# CH583SFR register map
Vendor: WCH Ltd.; Series: CH58x; File version: 1.1
CPU: RISC-V r0p0, little endian, no MPU, no FPU, 2 interrupt priority bits
Registers are 8-bit, read-write, reset 0x0 unless marked. A register's access mark holds for its fields unless they carry their own. Offsets are from the block's base; [hi:lo] are bit positions.

## I2C
Base 0x40004800
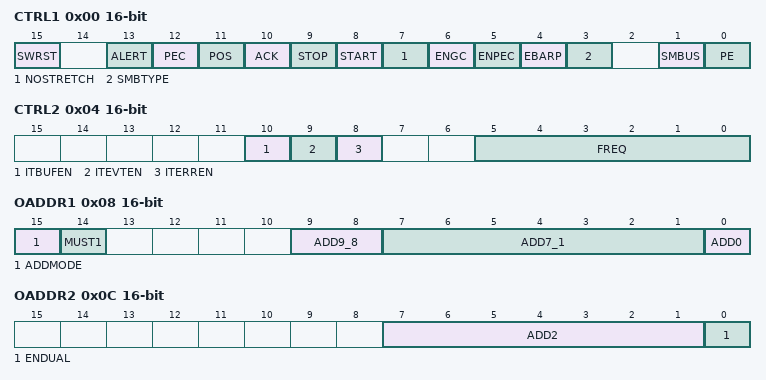
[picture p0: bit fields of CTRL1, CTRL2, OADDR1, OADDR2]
0x00 CTRL1 16-bit — RW, I2C control 1
  [15] SWRST — RW, Software reset
  [13] ALERT — RW, SMBus alert: 0=Releases SMBA pin high, 1=Drives SMBA pin low.
  [12] PEC — RW, Packet error checking: 0=No PEC transfer, 1=PEC transfer (in Tx or Rx mode)
  [11] POS — RW, Acknowledge/PEC Position (for data reception)
  [10] ACK — RW, Acknowledge enable
  [9] STOP — RW, Stop generation: master mode: 0=no stop, 1=stop after the current byte transfer or after the current Start condition is sent; slave mode: 0=no stop, 1=Release the SCL and SDA lines after the current byte transfer
  [8] START — RW, Start generation: master mode: 0=no start, 1=repeated start; slave mode: 0=no start, 1=start at bus free
  [7] NOSTRETCH — RW, Clock stretching disable (Slave mode)
  [6] ENGC — RW, General call enable
  [5] ENPEC — RW, PEC ebable
  [4] EBARP — RW, ARP enable
  [3] SMBTYPE — RW, SMBus type: 0=Device, 1=Host
  [1] SMBUS — RW, SMBUS mode: 0=I2C mode, 1=SMBUS mode
  [0] PE — RW, Peripheral enable
0x04 CTRL2 16-bit — RW, I2C control 2
  [10] ITBUFEN — RW, Buffer interrupt enable
  [9] ITEVTEN — RW, Event interrupt enable
  [8] ITERREN — RW, Error interrupt enable
  [5:0] FREQ — RW, Peripheral clock frequency, The minimum allowed frequency is 2 MHz,the maximum frequency is 36 MHz
0x08 OADDR1 16-bit — RW, I2C own address register 1
  [15] ADDMODE — RW, Addressing mode (slave mode): 0=7-bit slave address, 1=10-bit slave address
  [14] MUST1 — RW, Should always be kept at 1
  [9:8] ADD9_8 — RW, bit[9:8] of address in 10-bit addressing mode
  [7:1] ADD7_1 — RW, bit[7:1] of address
  [0] ADD0 — RW, bit0 of address in 10-bit addressing mode
0x0C OADDR2 16-bit — RW, I2C own address register 2
  [7:1] ADD2 — RW, bit[7:1] of address2
  [0] ENDUAL — RW, Dual addressing mode enable
0x10 DATAR 16-bit — RW, I2C data register
  [7:0] DATAR
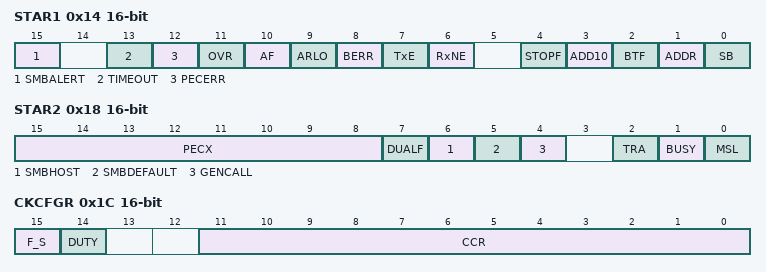
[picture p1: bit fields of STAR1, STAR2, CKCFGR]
0x14 STAR1 16-bit ro — R0, I2C stauts register 1
  [15] SMBALERT — RW0, SMBus alert flag
  [13] TIMEOUT — RW0, Timeout or Tlow error flag
  [12] PECERR — RW0, PEC Error flag in reception
  [11] OVR — RW0, Overrun/Underrun flag
  [10] AF — RW0, Acknowledge failure flag
  [9] ARLO — RW0, Arbitration lost flag (master mode)
  [8] BERR — RW0, Bus error flag
  [7] TxE — RO, Data register empty flag (transmitters)
  [6] RxNE — RO, Data register not empty flag (receivers)
  [4] STOPF — RO, Stop detection flag (slave mode)
  [3] ADD10 — RO, 10-bit header sent flag (Master mode)
  [2] BTF — RO, Byte transfer finished flag
  [1] ADDR — RW0, Address sent (master mode)/matched (slave mode) flag
  [0] SB — RW0, Start bit flag (Master mode)
0x18 STAR2 16-bit ro — R0, I2C status register 2
  [15:8] PECX — RO, Packet error checking register
  [7] DUALF — RO, Dual flag (Slave mode): 0=Received address matched with OAR1, 1=Received address matched with OAR2
  [6] SMBHOST — RO, SMBus host header (Slave mode) received flag
  [5] SMBDEFAULT — RO, SMBus device default address (Slave mode) received flag
  [4] GENCALL — RO, General call address (Slave mode) received flag
  [2] TRA — RO, Trans flag: 0=data bytes received, 1=data bytes transmitted
  [1] BUSY — RO, Bus busy flag
  [0] MSL — RO, Mode statu: 0=Slave mode, 1=Master mode
0x19 PEC ro — R0, I2C Packet error checking register
  [7:0] SPI0_FIFO_COUNT — RO, SPI0 FIFO count status
0x1C CKCFGR 16-bit — RW, I2C clock control register
  [15] F_S — RW, I2C master mode selection: 0=standard mode, 1=fast mode
  [14] DUTY — RW, Fm mode duty cycle: 0=L/H=2, 1=L/H=16/9
  [11:0] CCR — RW, Controls the SCL clock in Fm/Sm mode (Master mode)
0x20 RTR 16-bit reset 0x2 — RW, I2C trise register
  [5:0] TRISE — RW, Maximum rise time in Fm/Sm mode (Master mode)
